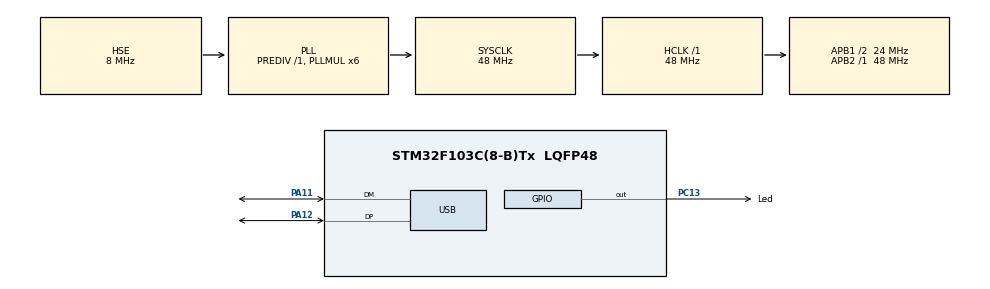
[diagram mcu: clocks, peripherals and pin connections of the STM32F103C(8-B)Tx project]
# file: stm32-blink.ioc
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FREERTOS.Tasks01=defaultTask,24,128,StartDefaultTask,Default,NULL,Dynamic,NULL,NULL;blinkTask,8,128,startBlinkTask,Default,NULL,Dynamic,NULL,NULL
FREERTOS.configTICK_RATE_HZ=100
FREERTOS.configTOTAL_HEAP_SIZE=12288
FREERTOS.configUSE_IDLE_HOOK=1
Mcu.Family=STM32F1
Mcu.Name=STM32F103C(8-B)Tx
Mcu.Package=LQFP48
NVIC.PriorityGroup=NVIC_PRIORITYGROUP_4
NVIC.TIM2_IRQn=true\:0\:0\:false\:false\:true\:false\:false\:true
NVIC.TimeBase=TIM2_IRQn
NVIC.TimeBaseIP=TIM2
NVIC.USB_LP_CAN1_RX0_IRQn=true\:0\:0\:false\:false\:true\:true\:false\:true
PA11.Mode=Device
PA11.Signal=USB_DM
PA12.Mode=Device
PA12.Signal=USB_DP
PA13.Mode=Serial_Wire
PA13.Signal=SYS_JTMS-SWDIO
PA14.Mode=Serial_Wire
PA14.Signal=SYS_JTCK-SWCLK
PC13-TAMPER-RTC.GPIO_Label=Led
PC13-TAMPER-RTC.GPIO_ModeDefaultOutputPP=GPIO_MODE_OUTPUT_PP
PC13-TAMPER-RTC.GPIO_PuPd=GPIO_NOPULL
PC13-TAMPER-RTC.GPIO_Speed=GPIO_SPEED_FREQ_LOW
PC13-TAMPER-RTC.PinState=GPIO_PIN_RESET
PC13-TAMPER-RTC.Signal=GPIO_Output
PC14-OSC32_IN.Mode=LSE-External-Oscillator
PC14-OSC32_IN.Signal=RCC_OSC32_IN
PC15-OSC32_OUT.Mode=LSE-External-Oscillator
PC15-OSC32_OUT.Signal=RCC_OSC32_OUT
PD0-OSC_IN.Mode=HSE-External-Oscillator
PD0-OSC_IN.Signal=RCC_OSC_IN
PD1-OSC_OUT.Mode=HSE-External-Oscillator
PD1-OSC_OUT.Signal=RCC_OSC_OUT
ProjectManager.HeapSize=0x400
ProjectManager.StackSize=0x800
ProjectManager.TargetToolchain=Makefile
RCC.AHBFreq_Value=48000000
RCC.APB1CLKDivider=RCC_HCLK_DIV2
RCC.APB1Freq_Value=24000000
RCC.APB1TimFreq_Value=48000000
RCC.APB2Freq_Value=48000000
RCC.APB2TimFreq_Value=48000000
RCC.HCLKFreq_Value=48000000
RCC.PLLMUL=RCC_PLL_MUL6
RCC.PLLSourceVirtual=RCC_PLLSOURCE_HSE
RCC.SYSCLKFreq_VALUE=48000000
RCC.SYSCLKSource=RCC_SYSCLKSOURCE_PLLCLK
RCC.USBFreq_Value=48000000
TIM4.Period=1000
TIM4.Prescaler=7200
USB_DEVICE.CLASS_NAME_FS=CDC
USB_DEVICE.VirtualMode=Cdc
USB_DEVICE.VirtualModeFS=Cdc_FS
VP_FREERTOS_VS_CMSIS_V2.Mode=CMSIS_V2
VP_SYS_VS_tim2.Mode=TIM2
VP_TIM4_VS_ClockSourceINT.Mode=Internal
VP_USB_DEVICE_VS_USB_DEVICE_CDC_FS.Mode=CDC_FS
board=custom

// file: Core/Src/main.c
/* USER CODE BEGIN Header */
/**
  ******************************************************************************
  * @file           : main.c
  * @brief          : Main program body
  ******************************************************************************
  * @attention
  *
  * <h2><center>&copy; Copyright (c) 2020 STMicroelectronics.
  * All rights reserved.</center></h2>
  *
  * This software component is licensed by ST under BSD 3-Clause license,
  * the "License"; You may not use this file except in compliance with the
  * License. You may obtain a copy of the License at:
  *                        opensource.org/licenses/BSD-3-Clause
  *
  ******************************************************************************
  */
/* USER CODE END Header */
#include "main.h"
#include "cmsis_os.h"
#include "usb_device.h"

/* USER CODE BEGIN Includes */
#include "usbd_cdc_if.h"
/* USER CODE END Includes */

TIM_HandleTypeDef htim4;

/* Definitions for defaultTask */
osThreadId_t defaultTaskHandle;
const osThreadAttr_t defaultTask_attributes = {
  .name = "defaultTask",
  .priority = (osPriority_t) osPriorityNormal,
  .stack_size = 128 * 4
};
/* Definitions for blinkTask */
osThreadId_t blinkTaskHandle;
const osThreadAttr_t blinkTask_attributes = {
  .name = "blinkTask",
  .priority = (osPriority_t) osPriorityLow,
  .stack_size = 128 * 4
};

void SystemClock_Config(void);
static void MX_GPIO_Init(void);
static void MX_TIM4_Init(void);
void StartDefaultTask(void *argument);
void startBlinkTask(void *argument);

int main(void)
{

  /* MCU Configuration--------------------------------------------------------*/

  /* Reset of all peripherals, Initializes the Flash interface and the Systick. */
  HAL_Init();

  /* Configure the system clock */
  SystemClock_Config();

  /* Initialize all configured peripherals */
  MX_GPIO_Init();
  MX_TIM4_Init();

  /* Init scheduler */
  osKernelInitialize();

  /* Create the thread(s) */
  /* creation of defaultTask */
  defaultTaskHandle = osThreadNew(StartDefaultTask, NULL, &defaultTask_attributes);

  /* creation of blinkTask */
  blinkTaskHandle = osThreadNew(startBlinkTask, NULL, &blinkTask_attributes);

  /* Start scheduler */
  osKernelStart();

  /* We should never get here as control is now taken by the scheduler */
  /* Infinite loop */
  /* USER CODE BEGIN WHILE */
  HAL_TIM_Base_Start(&htim4);
  HAL_TIM_Base_Start_IT(&htim4);
  while (1)
  {

    // HAL_GPIO_WritePin(Led_GPIO_Port, Led_Pin, GPIO_PIN_SET);
    // HAL_Delay(300);
    // HAL_GPIO_WritePin(Led_GPIO_Port, Led_Pin, GPIO_PIN_RESET);
    // HAL_Delay(20);
    /* USER CODE END WHILE */

  }
}

void SystemClock_Config(void)
{
  RCC_OscInitTypeDef RCC_OscInitStruct = {0};
  RCC_ClkInitTypeDef RCC_ClkInitStruct = {0};
  RCC_PeriphCLKInitTypeDef PeriphClkInit = {0};

  /** Initializes the RCC Oscillators according to the specified parameters
  * in the RCC_OscInitTypeDef structure.
  */
  RCC_OscInitStruct.OscillatorType = RCC_OSCILLATORTYPE_HSE;
  RCC_OscInitStruct.HSEState = RCC_HSE_ON;
  RCC_OscInitStruct.HSEPredivValue = RCC_HSE_PREDIV_DIV1;
  RCC_OscInitStruct.HSIState = RCC_HSI_ON;
  RCC_OscInitStruct.PLL.PLLState = RCC_PLL_ON;
  RCC_OscInitStruct.PLL.PLLSource = RCC_PLLSOURCE_HSE;
  RCC_OscInitStruct.PLL.PLLMUL = RCC_PLL_MUL6;
  if (HAL_RCC_OscConfig(&RCC_OscInitStruct) != HAL_OK)
  {
    Error_Handler();
  }
  /** Initializes the CPU, AHB and APB buses clocks
  */
  RCC_ClkInitStruct.ClockType = RCC_CLOCKTYPE_HCLK|RCC_CLOCKTYPE_SYSCLK
                              |RCC_CLOCKTYPE_PCLK1|RCC_CLOCKTYPE_PCLK2;
  RCC_ClkInitStruct.SYSCLKSource = RCC_SYSCLKSOURCE_PLLCLK;
  RCC_ClkInitStruct.AHBCLKDivider = RCC_SYSCLK_DIV1;
  RCC_ClkInitStruct.APB1CLKDivider = RCC_HCLK_DIV2;
  RCC_ClkInitStruct.APB2CLKDivider = RCC_HCLK_DIV1;

  if (HAL_RCC_ClockConfig(&RCC_ClkInitStruct, FLASH_LATENCY_1) != HAL_OK)
  {
    Error_Handler();
  }
  PeriphClkInit.PeriphClockSelection = RCC_PERIPHCLK_USB;
  PeriphClkInit.UsbClockSelection = RCC_USBCLKSOURCE_PLL;
  if (HAL_RCCEx_PeriphCLKConfig(&PeriphClkInit) != HAL_OK)
  {
    Error_Handler();
  }
}

static void MX_TIM4_Init(void)
{

  TIM_ClockConfigTypeDef sClockSourceConfig = {0};
  TIM_MasterConfigTypeDef sMasterConfig = {0};

  htim4.Instance = TIM4;
  htim4.Init.Prescaler = 7200;
  htim4.Init.CounterMode = TIM_COUNTERMODE_UP;
  htim4.Init.Period = 1000;
  htim4.Init.ClockDivision = TIM_CLOCKDIVISION_DIV1;
  htim4.Init.AutoReloadPreload = TIM_AUTORELOAD_PRELOAD_DISABLE;
  if (HAL_TIM_Base_Init(&htim4) != HAL_OK)
  {
    Error_Handler();
  }
  sClockSourceConfig.ClockSource = TIM_CLOCKSOURCE_INTERNAL;
  if (HAL_TIM_ConfigClockSource(&htim4, &sClockSourceConfig) != HAL_OK)
  {
    Error_Handler();
  }
  sMasterConfig.MasterOutputTrigger = TIM_TRGO_RESET;
  sMasterConfig.MasterSlaveMode = TIM_MASTERSLAVEMODE_DISABLE;
  if (HAL_TIMEx_MasterConfigSynchronization(&htim4, &sMasterConfig) != HAL_OK)
  {
    Error_Handler();
  }

}

static void MX_GPIO_Init(void)
{
  GPIO_InitTypeDef GPIO_InitStruct = {0};

  /* GPIO Ports Clock Enable */
  __HAL_RCC_GPIOC_CLK_ENABLE();
  __HAL_RCC_GPIOD_CLK_ENABLE();
  __HAL_RCC_GPIOA_CLK_ENABLE();

  /*Configure GPIO pin Output Level */
  HAL_GPIO_WritePin(Led_GPIO_Port, Led_Pin, GPIO_PIN_RESET);

  /*Configure GPIO pin : Led_Pin */
  GPIO_InitStruct.Pin = Led_Pin;
  GPIO_InitStruct.Mode = GPIO_MODE_OUTPUT_PP;
  GPIO_InitStruct.Pull = GPIO_NOPULL;
  GPIO_InitStruct.Speed = GPIO_SPEED_FREQ_LOW;
  HAL_GPIO_Init(Led_GPIO_Port, &GPIO_InitStruct);

}

void StartDefaultTask(void *argument)
{
  /* init code for USB_DEVICE */
  MX_USB_DEVICE_Init();
  /* USER CODE BEGIN 5 */
  uint16_t deflt = 22;
  /* Infinite loop */
  for(;;)
  {
    osDelay(1);
    deflt++;
  }
  /* USER CODE END 5 */
}

void startBlinkTask(void *argument)
{
  /* USER CODE BEGIN startBlinkTask */

  /* Infinite loop */
  for(;;)
  {
    HAL_GPIO_WritePin(Led_GPIO_Port, Led_Pin, GPIO_PIN_SET);
    osDelay(500);
    HAL_GPIO_WritePin(Led_GPIO_Port, Led_Pin, GPIO_PIN_RESET);
    osDelay(10);
    uint32_t freemem = xPortGetFreeHeapSize();
    freemem++;
    char buf[13] = "StudyTonight";
    CDC_Transmit_FS((uint8_t *)buf, sizeof(buf));
  }
  /* USER CODE END startBlinkTask */
}

void HAL_TIM_PeriodElapsedCallback(TIM_HandleTypeDef *htim)
{
  if (htim->Instance == TIM2) {
    HAL_IncTick();
  }
}

void Error_Handler(void)
{
}

/************************ (C) COPYRIGHT STMicroelectronics *****END OF FILE****/

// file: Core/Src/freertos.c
/* USER CODE BEGIN Header */
/**
  ******************************************************************************
  * File Name          : freertos.c
  * Description        : Code for freertos applications
  ******************************************************************************
  * @attention
  *
  * <h2><center>&copy; Copyright (c) 2020 STMicroelectronics.
  * All rights reserved.</center></h2>
  *
  * This software component is licensed by ST under Ultimate Liberty license
  * SLA0044, the "License"; You may not use this file except in compliance with
  * the License. You may obtain a copy of the License at:
  *                             www.st.com/SLA0044
  *
  ******************************************************************************
  */
/* USER CODE END Header */

#include "FreeRTOS.h"
#include "task.h"
#include "main.h"

/* USER CODE BEGIN Variables */
char pcWrightBuffer[1024];
/* USER CODE END Variables */

/* Hook prototypes */
void vApplicationIdleHook(void);

/* USER CODE BEGIN 2 */
__weak void vApplicationIdleHook( void )
{
   /* vApplicationIdleHook() will only be called if configUSE_IDLE_HOOK is set
   to 1 in FreeRTOSConfig.h. It will be called on each iteration of the idle
   task. It is essential that code added to this hook function never attempts
   to block in any way (for example, call xQueueReceive() with a block time
   specified, or call vTaskDelay()). If the application makes use of the
   vTaskDelete() API function (as this demo application does) then it is also
   important that vApplicationIdleHook() is permitted to return to its calling
   function, because it is the responsibility of the idle task to clean up
   memory allocated by the kernel to any task that has since been deleted. */
}
/* USER CODE END 2 */

/************************ (C) COPYRIGHT STMicroelectronics *****END OF FILE****/
